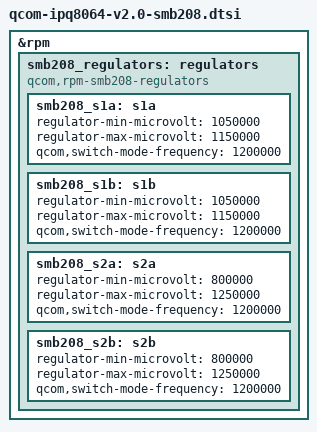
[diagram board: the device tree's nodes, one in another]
// SPDX-License-Identifier: GPL-2.0

#include "qcom-ipq8064-v2.0.dtsi"

&rpm {
	smb208_regulators: regulators {
		compatible = "qcom,rpm-smb208-regulators";

		smb208_s1a: s1a {
			regulator-min-microvolt = <1050000>;
			regulator-max-microvolt = <1150000>;

			qcom,switch-mode-frequency = <1200000>;
		};

		smb208_s1b: s1b {
			regulator-min-microvolt = <1050000>;
			regulator-max-microvolt = <1150000>;

			qcom,switch-mode-frequency = <1200000>;
		};

		smb208_s2a: s2a {
			regulator-min-microvolt = < 800000>;
			regulator-max-microvolt = <1250000>;

			qcom,switch-mode-frequency = <1200000>;
		};

		smb208_s2b: s2b {
			regulator-min-microvolt = < 800000>;
			regulator-max-microvolt = <1250000>;

			qcom,switch-mode-frequency = <1200000>;
		};
	};
};
